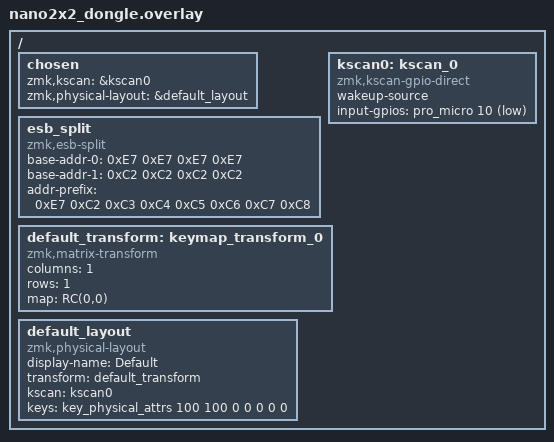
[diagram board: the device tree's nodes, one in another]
#include <dt-bindings/zmk/matrix_transform.h>
#include <physical_layouts.dtsi>

/ {
    chosen {
        zmk,kscan = &kscan0;
        zmk,physical-layout = &default_layout;
    };

    esb_split {
        compatible = "zmk,esb-split";
        base-addr-0 = <0xE7 0xE7 0xE7 0xE7>;
        base-addr-1 = <0xC2 0xC2 0xC2 0xC2>;
        addr-prefix = <0xE7 0xC2 0xC3 0xC4 0xC5 0xC6 0xC7 0xC8>;
    };

    kscan0: kscan_0 {
        compatible = "zmk,kscan-gpio-direct";
        wakeup-source;
        input-gpios = <&pro_micro 10 (GPIO_ACTIVE_LOW | GPIO_PULL_UP)>;
    };

    default_transform: keymap_transform_0 {
        compatible = "zmk,matrix-transform";
        columns = <1>;
        rows = <1>;

        map = <
            RC(0,0)
        >;
    };

    default_layout: default_layout {
        compatible = "zmk,physical-layout";
        display-name = "Default";
        transform = <&default_transform>;
        kscan = <&kscan0>;
        keys
            = <&key_physical_attrs 100 100 0 0 0 0 0>
            ;
    };
};
